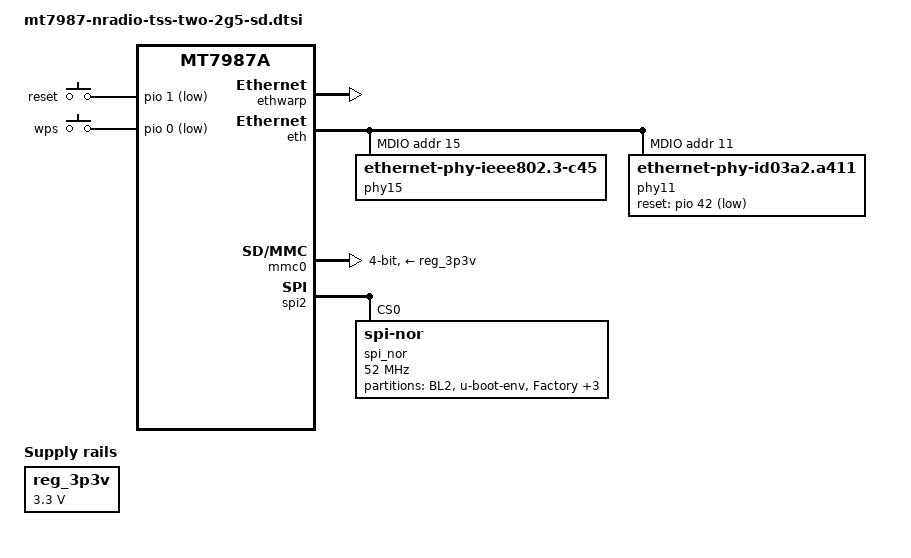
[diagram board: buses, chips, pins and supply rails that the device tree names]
/dts-v1/;
/* SPDX-License-Identifier: (GPL-2.0-only OR MIT) */

#include "../mt7987a.dtsi"
#include "../mt7987-pinctrl.dtsi"
#include <dt-bindings/input/input.h>
#include <dt-bindings/interrupt-controller/irq.h>
#include <dt-bindings/interrupt-controller/arm-gic.h>
#include <dt-bindings/phy/phy.h>
#include <dt-bindings/reset/ti-syscon.h>
#include <dt-bindings/clock/mediatek,mt7987-clk.h>
#include <dt-bindings/pinctrl/mt65xx.h>

/ {
	chosen {
		bootargs = "console=ttyS0,115200n1 loglevel=8  \
			    earlycon=uart8250,mmio32,0x11000000 \
			    pci=pcie_bus_perf";
	};

	gkeys: gpio-keys {
		compatible = "gpio-keys";

		reset {
			label = "reset";
			linux,code = <KEY_RESTART>;
			gpios = <&pio 1 GPIO_ACTIVE_LOW>;
		};

		wps {
			label = "wps";
			linux,code = <KEY_WPS_BUTTON>;
			gpios = <&pio 0 GPIO_ACTIVE_LOW>;
		};
	};

	reg_3p3v: regulator-3p3v {
		compatible = "regulator-fixed";
		regulator-name = "fixed-3.3V";
		regulator-min-microvolt = <3300000>;
		regulator-max-microvolt = <3300000>;
		regulator-boot-on;
		regulator-always-on;
	};
};

&netsys {
	ethwarp: syscon@15031000 {
		compatible = "mediatek,mt7988-ethwarp", "syscon";
		reg = <0 0x15031000 0 0x1000>;
		#clock-cells = <1>;
	};

	eth: ethernet@15100000 {
		compatible = "mediatek,mt7987-eth";
		reg = <0 0x15100000 0 0x80000>,
		      <0 0x15400000 0 0x20000>;
		interrupts = <GIC_SPI 189 IRQ_TYPE_LEVEL_HIGH>,
			     <GIC_SPI 190 IRQ_TYPE_LEVEL_HIGH>,
			     <GIC_SPI 191 IRQ_TYPE_LEVEL_HIGH>,
			     <GIC_SPI 192 IRQ_TYPE_LEVEL_HIGH>,
			     <GIC_SPI 196 IRQ_TYPE_LEVEL_HIGH>,
			     <GIC_SPI 197 IRQ_TYPE_LEVEL_HIGH>,
			     <GIC_SPI 198 IRQ_TYPE_LEVEL_HIGH>,
			     <GIC_SPI 199 IRQ_TYPE_LEVEL_HIGH>;
		clocks = <&ethsys CK_ETHDMA_FE_EN>,
			 <&ethsys CK_ETHDMA_GP2_EN>,
			 <&ethsys CK_ETHDMA_GP1_EN>,
			 <&ethsys CK_ETHDMA_GP3_EN>,
			 <&sgmiisys0 CK_SGM0_TX_EN>,
			 <&sgmiisys0 CK_SGM0_RX_EN>,
			 <&sgmiisys1 CK_SGM1_TX_EN>,
			 <&sgmiisys1 CK_SGM1_RX_EN>,
			 <&topckgen CK_TOP_SGM_0_SEL>,
			 <&topckgen CK_TOP_SGM_1_SEL>,
			 <&topckgen CK_TOP_ETH_GMII_SEL>,
			 <&topckgen CK_TOP_ETH_REFCK_50M_SEL>,
			 <&topckgen CK_TOP_ETH_SYS_200M_SEL>,
			 <&topckgen CK_TOP_ETH_SYS_SEL>,
			 <&topckgen CK_TOP_ETH_XGMII_SEL>,
			 <&topckgen CK_TOP_ETH_MII_SEL>,
			 <&topckgen CK_TOP_NETSYS_SEL>,
			 <&topckgen CK_TOP_NETSYS_500M_SEL>,
			 <&topckgen CK_TOP_NETSYS_2X_SEL>;
		clock-names = "fe", "gp2", "gp1", "gp3", "sgmii_tx250m",
			      "sgmii_rx250m", "sgmii2_tx250m", "sgmii2_rx250m",
			      "top_sgm0_sel", "top_sgm1_sel", "top_eth_gmii_sel",
			      "top_eth_refck_50m_sel", "top_eth_sys_200m_sel",
			      "top_eth_sys_sel", "top_eth_xgmii_sel",
			      "top_eth_mii_sel", "top_netsys_sel",
			      "top_netsys_500m_sel", "top_netsys_pao_2x_sel";
		assigned-clocks = <&topckgen CK_TOP_NETSYS_2X_SEL>,
				  <&topckgen CK_TOP_SGM_0_SEL>,
				  <&topckgen CK_TOP_SGM_1_SEL>;
		assigned-clock-parents = <&apmixedsys CK_APMIXED_NET2PLL>,
					 <&apmixedsys CK_APMIXED_SGMPLL>,
					 <&apmixedsys CK_APMIXED_SGMPLL>;
		mediatek,ethsys = <&ethsys>;
		mediatek,sgmiisys = <&sgmiisys0>, <&sgmiisys1>;
		mediatek,infracfg = <&topmisc>;
		mediatek,toprgu = <&watchdog>;
		pinctrl-names = "default";
		pinctrl-0 = <&mdio0_pins>;
		#reset-cells = <1>;
		#address-cells = <1>;
		#size-cells = <0>;
		status = "disabled";

		gmac0: mac@0 {
			compatible = "mediatek,eth-mac";
			reg = <0>;
			mac-type = "gdm";
			phy-mode = "2500base-x";
			phy-handle = <&phy11>;
		};

		gmac1: mac@1 {
			compatible = "mediatek,eth-mac";
			reg = <1>;
			mac-type = "xgdm";
			phy-mode = "internal";
			phy-handle = <&phy15>;
		};

		gmac2: mac@2 {
			compatible = "mediatek,eth-mac";
			reg = <2>;
			phy-mode = "internal";

			fixed-link {
				speed = <2500>;
				full-duplex;
				pause;
			};
		};

		mdio: mdio-bus {
			#address-cells = <1>;
			#size-cells = <0>;
			// reset-gpios = <&pio 48 1>;
			// reset-delay-us = <10000>;

			phy15: phy@15 {
				pinctrl-names = "i2p5gbe-led";
				pinctrl-0 = <&i2p5gbe_led0_pins>;
				compatible = "ethernet-phy-ieee802.3-c45";
				interrupts = <GIC_SPI 286 IRQ_TYPE_LEVEL_HIGH>;
				interrupt-parent = <&gic>;
				reg = <15>;
				phy-mode = "internal";
			};

			phy11: phy@11 {
				compatible = "ethernet-phy-id03a2.a411";
				reg = <11>;
				reset-gpios = <&pio 42 1>;
				reset-assert-us = <10000>;
				reset-deassert-us = <10000>;
				phy-mode = "2500base-x";
				full-duplex;
				pause;
				airoha,phy-handle;
			};
		};
	};

	hnat: hnat@15000000 {
		compatible = "mediatek,mtk-hnat_v5";
		reg = <0 0x15100000 0 0x80000>;
		interrupts = <GIC_SPI 198 IRQ_TYPE_LEVEL_HIGH>;
		resets = <&ethsys 0>;
		reset-names = "mtketh";
		status = "disabled";
	};

	crypto: crypto@15600000 {
		compatible = "inside-secure,safexcel-eip197b",
			     "security-ip-197-srv";
		reg = <0 0x15600000 0 0x180000>;
		interrupts = <GIC_SPI 214 IRQ_TYPE_LEVEL_HIGH>,
			     <GIC_SPI 215 IRQ_TYPE_LEVEL_HIGH>,
			     <GIC_SPI 216 IRQ_TYPE_LEVEL_HIGH>,
			     <GIC_SPI 217 IRQ_TYPE_LEVEL_HIGH>;
		interrupt-names = "ring0", "ring1", "ring2", "ring3";
		eth = <&eth>;
		status = "disabled";
	};
};

&crypto {
	status = "okay";
};

&eth {
	status = "okay";
};

&hnat {
	mtketh-wan = "eth0";
	mtketh-lan = "eth1";
	mtketh-lan2 = "eth2";
	mtketh-ppd = "eth2";
	mtketh-max-gmac = <3>;
	mtketh-ppe-num = <2>;
	ext-devices = "eth3";
	status = "okay";
};

/* Disable spi1 node since MSDC and spi1 share pins on MT7987. */
&spi1 {
	status = "disabled";
};

&mmc0 {
	pinctrl-names = "default", "state_uhs";
	pinctrl-0 = <&sd_pins_default>;
	pinctrl-1 = <&sd_pins_uhs>;
	bus-width = <4>;
	max-frequency = <50000000>;
	cap-sd-highspeed;
	vmmc-supply = <&reg_3p3v>;
	vqmmc-supply = <&reg_3p3v>;
	no-mmc;
	no-sdio;
	broken-cd;
	status = "okay";
};

&spi2 {
	pinctrl-names = "default";
	pinctrl-0 = <&spi2_flash_pins>;
	status = "okay";
	#address-cells = <1>;
	#size-cells = <0>;

	spi_nor@0 {
		#address-cells = <1>;
		#size-cells = <1>;
		compatible = "jedec,spi-nor";
		spi-cal-enable;
		spi-cal-mode = "read-data";
		spi-cal-datalen = <7>;
		spi-cal-data = /bits/ 8 <
			0x53 0x46 0x5F 0x42 0x4F 0x4F 0x54>; /* SF_BOOT */
		spi-cal-addrlen = <1>;
		spi-cal-addr = /bits/ 32 <0x0>;
		reg = <0>;
		spi-max-frequency = <52000000>;
		spi-tx-bus-width = <4>;
		spi-rx-bus-width = <4>;

		partition@0 {
			label = "BL2";
			reg = <0x00000 0x0040000>;
			read-only;
		};
		partition@40000 {
			label = "u-boot-env";
			reg = <0x40000 0x0010000>;
		};
		factory: partition@50000 {
			label = "Factory";
			reg = <0x50000 0x0100000>;
		};
		partition@150000 {
			label = "bdinfo";
			reg = <0x150000 0x0080000>;
		};
		partition@1D0000 {
			label = "FIP";
			reg = <0x1D0000 0x0100000>;
		};
		partition@2D0000 {
			label = "firmware";
			reg = <0x2D0000 0x1D30000>;
		};
	};
};
